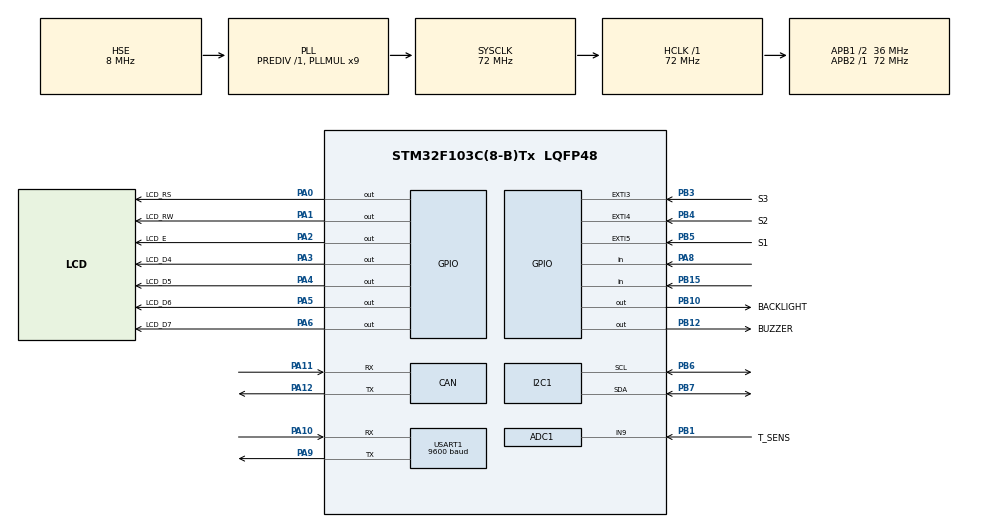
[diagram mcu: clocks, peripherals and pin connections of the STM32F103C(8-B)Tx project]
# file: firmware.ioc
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Mcu.Family=STM32F1
ADC1.ContinuousConvMode=ENABLE
PB4.GPIO_ModeDefaultEXTI=GPIO_MODE_IT_RISING_FALLING
USART1.BaudRate=9600
NVIC.EXTI3_IRQn=true\:0\:0\:false\:false\:true\:true\:true
PA11.Mode=Master
PA6.GPIO_Label=LCD_D7
PB3.GPIO_ModeDefaultEXTI=GPIO_MODE_IT_RISING_FALLING
PB15.Signal=GPIO_Input
RCC.SYSCLKSource=RCC_SYSCLKSOURCE_PLLCLK
ProjectManager.StackSize=0x400
PD1-OSC_OUT.Signal=RCC_OSC_OUT
PA12.Signal=CAN_TX
RCC.HCLKFreq_Value=72000000
RCC.APB2TimFreq_Value=72000000
PB6.Signal=I2C1_SCL
PB6.Mode=I2C
RCC.AHBFreq_Value=72000000
ADC1.Channel-0\#ChannelRegularConversion=ADC_CHANNEL_9
RCC.PLLMUL=RCC_PLL_MUL9
PB12.GPIO_Label=BUZZER
PB3.GPIO_PuPd=GPIO_PULLUP
PB1.GPIO_Label=T_SENS
PB7.Signal=I2C1_SDA
PA8.Signal=GPIO_Input
CAN.CalculateTimeQuantum=444.44444444444446
ADC1.SamplingTime-0\#ChannelRegularConversion=ADC_SAMPLETIME_1CYCLE_5
Mcu.Package=LQFP48
PB1.Signal=ADCx_IN9
PA6.Signal=GPIO_Output
PA2.GPIO_Label=LCD_E
PA10.Signal=USART1_RX
SH.ADCx_IN9.0=ADC1_IN9,IN9
PB5.GPIO_Label=S1
RCC.APB1TimFreq_Value=72000000
PA4.GPIO_Label=LCD_D5
PB4.Signal=GPXTI4
PA3.Signal=GPIO_Output
PB3.GPIO_Label=S3
PB5.GPIO_ModeDefaultEXTI=GPIO_MODE_IT_RISING_FALLING
RCC.PLLSourceVirtual=RCC_PLLSOURCE_HSE
NVIC.EXTI4_IRQn=true\:0\:0\:false\:false\:true\:true\:true
ADC1.Rank-0\#ChannelRegularConversion=1
PD1-OSC_OUT.Mode=HSE-External-Oscillator
PA10.Mode=Asynchronous
PD0-OSC_IN.Signal=RCC_OSC_IN
RCC.APB1CLKDivider=RCC_HCLK_DIV2
VP_SYS_VS_ND.Mode=No_Debug
CAN.CalculateTimeBit=2222
PA0-WKUP.GPIO_Label=LCD_RS
PA0-WKUP.Signal=GPIO_Output
RCC.ADCPresc=RCC_ADCPCLK2_DIV6
PA9.Mode=Asynchronous
CAN.BS2=CAN_BS2_2TQ
CAN.BS1=CAN_BS1_2TQ
ProjectManager.TargetToolchain=Makefile
PB10.GPIO_Label=BACKLIGHT
PA9.Signal=USART1_TX
PB4.GPIO_PuPd=GPIO_PULLUP
RCC.USBFreq_Value=72000000
PA1.Signal=GPIO_Output
PD0-OSC_IN.Mode=HSE-External-Oscillator
PB10.Signal=GPIO_Output
PA5.Signal=GPIO_Output
board=custom
RCC.APB2Freq_Value=72000000
PB4.GPIO_Label=S2
PA1.GPIO_Label=LCD_RW
Mcu.Name=STM32F103C(8-B)Tx
PA2.Signal=GPIO_Output
PB3.Signal=GPXTI3
PA4.Signal=GPIO_Output
RCC.SYSCLKFreq_VALUE=72000000
PB5.Signal=GPXTI5
ADC1.master=1
PA12.Mode=Master
PA5.GPIO_Label=LCD_D6
PB5.GPIO_PuPd=GPIO_PULLUP
USART1.VirtualMode=VM_ASYNC
PB7.Mode=I2C
PA11.Signal=CAN_RX
NVIC.EXTI9_5_IRQn=true\:0\:0\:false\:false\:true\:true\:true
ProjectManager.HeapSize=0x200
NVIC.PriorityGroup=NVIC_PRIORITYGROUP_4
ADC1.NbrOfConversionFlag=1
RCC.APB1Freq_Value=36000000
PB12.Signal=GPIO_Output
PA3.GPIO_Label=LCD_D4

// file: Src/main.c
/* USER CODE BEGIN Header */
/**
  ******************************************************************************
  * @file           : main.c
  * @brief          : Main program body
  ******************************************************************************
  * @attention
  *
  * <h2><center>&copy; Copyright (c) 2020 STMicroelectronics.
  * All rights reserved.</center></h2>
  *
  * This software component is licensed by ST under BSD 3-Clause license,
  * the "License"; You may not use this file except in compliance with the
  * License. You may obtain a copy of the License at:
  *                        opensource.org/licenses/BSD-3-Clause
  *
  ******************************************************************************
  */
/* USER CODE END Header */

#include "main.h"

/* USER CODE BEGIN Includes */

#include "logic.h"
#include "system.h"

/* USER CODE END Includes */

ADC_HandleTypeDef hadc1;

CAN_HandleTypeDef hcan;

I2C_HandleTypeDef hi2c1;

UART_HandleTypeDef huart1;

void SystemClock_Config(void);
static void MX_GPIO_Init(void);
static void MX_ADC1_Init(void);
static void MX_CAN_Init(void);
static void MX_I2C1_Init(void);
static void MX_USART1_UART_Init(void);

int main(void)
{

  /* MCU Configuration--------------------------------------------------------*/

  /* Reset of all peripherals, Initializes the Flash interface and the Systick. */
  HAL_Init();

  /* Configure the system clock */
  SystemClock_Config();

  /* Initialize all configured peripherals */
  MX_GPIO_Init();
  MX_ADC1_Init();
  MX_CAN_Init();
  MX_I2C1_Init();
  MX_USART1_UART_Init();
  /* USER CODE BEGIN 2 */

  system_init();
  logic_init();

  /* USER CODE END 2 */

  /* Infinite loop */
  /* USER CODE BEGIN WHILE */
  while (1)
  {
    logic_update();
    /* USER CODE END WHILE */

  }
}

void SystemClock_Config(void)
{
  RCC_OscInitTypeDef RCC_OscInitStruct = {0};
  RCC_ClkInitTypeDef RCC_ClkInitStruct = {0};
  RCC_PeriphCLKInitTypeDef PeriphClkInit = {0};

  /** Initializes the CPU, AHB and APB busses clocks
  */
  RCC_OscInitStruct.OscillatorType = RCC_OSCILLATORTYPE_HSE;
  RCC_OscInitStruct.HSEState = RCC_HSE_ON;
  RCC_OscInitStruct.HSEPredivValue = RCC_HSE_PREDIV_DIV1;
  RCC_OscInitStruct.HSIState = RCC_HSI_ON;
  RCC_OscInitStruct.PLL.PLLState = RCC_PLL_ON;
  RCC_OscInitStruct.PLL.PLLSource = RCC_PLLSOURCE_HSE;
  RCC_OscInitStruct.PLL.PLLMUL = RCC_PLL_MUL9;
  if (HAL_RCC_OscConfig(&RCC_OscInitStruct) != HAL_OK)
  {
    Error_Handler();
  }
  /** Initializes the CPU, AHB and APB busses clocks
  */
  RCC_ClkInitStruct.ClockType = RCC_CLOCKTYPE_HCLK|RCC_CLOCKTYPE_SYSCLK
                              |RCC_CLOCKTYPE_PCLK1|RCC_CLOCKTYPE_PCLK2;
  RCC_ClkInitStruct.SYSCLKSource = RCC_SYSCLKSOURCE_PLLCLK;
  RCC_ClkInitStruct.AHBCLKDivider = RCC_SYSCLK_DIV1;
  RCC_ClkInitStruct.APB1CLKDivider = RCC_HCLK_DIV2;
  RCC_ClkInitStruct.APB2CLKDivider = RCC_HCLK_DIV1;

  if (HAL_RCC_ClockConfig(&RCC_ClkInitStruct, FLASH_LATENCY_2) != HAL_OK)
  {
    Error_Handler();
  }
  PeriphClkInit.PeriphClockSelection = RCC_PERIPHCLK_ADC;
  PeriphClkInit.AdcClockSelection = RCC_ADCPCLK2_DIV6;
  if (HAL_RCCEx_PeriphCLKConfig(&PeriphClkInit) != HAL_OK)
  {
    Error_Handler();
  }
}

static void MX_ADC1_Init(void)
{

  ADC_ChannelConfTypeDef sConfig = {0};

  /** Common config
  */
  hadc1.Instance = ADC1;
  hadc1.Init.ScanConvMode = ADC_SCAN_DISABLE;
  hadc1.Init.ContinuousConvMode = ENABLE;
  hadc1.Init.DiscontinuousConvMode = DISABLE;
  hadc1.Init.ExternalTrigConv = ADC_SOFTWARE_START;
  hadc1.Init.DataAlign = ADC_DATAALIGN_RIGHT;
  hadc1.Init.NbrOfConversion = 1;
  if (HAL_ADC_Init(&hadc1) != HAL_OK)
  {
    Error_Handler();
  }
  /** Configure Regular Channel
  */
  sConfig.Channel = ADC_CHANNEL_9;
  sConfig.Rank = ADC_REGULAR_RANK_1;
  sConfig.SamplingTime = ADC_SAMPLETIME_1CYCLE_5;
  if (HAL_ADC_ConfigChannel(&hadc1, &sConfig) != HAL_OK)
  {
    Error_Handler();
  }

}

static void MX_CAN_Init(void)
{

  hcan.Instance = CAN1;
  hcan.Init.Prescaler = 16;
  hcan.Init.Mode = CAN_MODE_NORMAL;
  hcan.Init.SyncJumpWidth = CAN_SJW_1TQ;
  hcan.Init.TimeSeg1 = CAN_BS1_2TQ;
  hcan.Init.TimeSeg2 = CAN_BS2_2TQ;
  hcan.Init.TimeTriggeredMode = DISABLE;
  hcan.Init.AutoBusOff = DISABLE;
  hcan.Init.AutoWakeUp = DISABLE;
  hcan.Init.AutoRetransmission = DISABLE;
  hcan.Init.ReceiveFifoLocked = DISABLE;
  hcan.Init.TransmitFifoPriority = DISABLE;
  if (HAL_CAN_Init(&hcan) != HAL_OK)
  {
    Error_Handler();
  }

}

static void MX_I2C1_Init(void)
{

  hi2c1.Instance = I2C1;
  hi2c1.Init.ClockSpeed = 100000;
  hi2c1.Init.DutyCycle = I2C_DUTYCYCLE_2;
  hi2c1.Init.OwnAddress1 = 0;
  hi2c1.Init.AddressingMode = I2C_ADDRESSINGMODE_7BIT;
  hi2c1.Init.DualAddressMode = I2C_DUALADDRESS_DISABLE;
  hi2c1.Init.OwnAddress2 = 0;
  hi2c1.Init.GeneralCallMode = I2C_GENERALCALL_DISABLE;
  hi2c1.Init.NoStretchMode = I2C_NOSTRETCH_DISABLE;
  if (HAL_I2C_Init(&hi2c1) != HAL_OK)
  {
    Error_Handler();
  }

}

static void MX_USART1_UART_Init(void)
{

  huart1.Instance = USART1;
  huart1.Init.BaudRate = 9600;
  huart1.Init.WordLength = UART_WORDLENGTH_8B;
  huart1.Init.StopBits = UART_STOPBITS_1;
  huart1.Init.Parity = UART_PARITY_NONE;
  huart1.Init.Mode = UART_MODE_TX_RX;
  huart1.Init.HwFlowCtl = UART_HWCONTROL_NONE;
  huart1.Init.OverSampling = UART_OVERSAMPLING_16;
  if (HAL_UART_Init(&huart1) != HAL_OK)
  {
    Error_Handler();
  }

}

static void MX_GPIO_Init(void)
{
  GPIO_InitTypeDef GPIO_InitStruct = {0};

  /* GPIO Ports Clock Enable */
  __HAL_RCC_GPIOD_CLK_ENABLE();
  __HAL_RCC_GPIOA_CLK_ENABLE();
  __HAL_RCC_GPIOB_CLK_ENABLE();

  /*Configure GPIO pin Output Level */
  HAL_GPIO_WritePin(GPIOA, LCD_RS_Pin|LCD_RW_Pin|LCD_E_Pin|LCD_D4_Pin
                          |LCD_D5_Pin|LCD_D6_Pin|LCD_D7_Pin, GPIO_PIN_RESET);

  /*Configure GPIO pin Output Level */
  HAL_GPIO_WritePin(GPIOB, BACKLIGHT_Pin|BUZZER_Pin, GPIO_PIN_RESET);

  /*Configure GPIO pins : LCD_RS_Pin LCD_RW_Pin LCD_E_Pin LCD_D4_Pin
                           LCD_D5_Pin LCD_D6_Pin LCD_D7_Pin */
  GPIO_InitStruct.Pin = LCD_RS_Pin|LCD_RW_Pin|LCD_E_Pin|LCD_D4_Pin
                          |LCD_D5_Pin|LCD_D6_Pin|LCD_D7_Pin;
  GPIO_InitStruct.Mode = GPIO_MODE_OUTPUT_PP;
  GPIO_InitStruct.Pull = GPIO_NOPULL;
  GPIO_InitStruct.Speed = GPIO_SPEED_FREQ_LOW;
  HAL_GPIO_Init(GPIOA, &GPIO_InitStruct);

  /*Configure GPIO pins : BACKLIGHT_Pin BUZZER_Pin */
  GPIO_InitStruct.Pin = BACKLIGHT_Pin|BUZZER_Pin;
  GPIO_InitStruct.Mode = GPIO_MODE_OUTPUT_PP;
  GPIO_InitStruct.Pull = GPIO_NOPULL;
  GPIO_InitStruct.Speed = GPIO_SPEED_FREQ_LOW;
  HAL_GPIO_Init(GPIOB, &GPIO_InitStruct);

  /*Configure GPIO pin : PB15 */
  GPIO_InitStruct.Pin = GPIO_PIN_15;
  GPIO_InitStruct.Mode = GPIO_MODE_INPUT;
  GPIO_InitStruct.Pull = GPIO_NOPULL;
  HAL_GPIO_Init(GPIOB, &GPIO_InitStruct);

  /*Configure GPIO pin : PA8 */
  GPIO_InitStruct.Pin = GPIO_PIN_8;
  GPIO_InitStruct.Mode = GPIO_MODE_INPUT;
  GPIO_InitStruct.Pull = GPIO_NOPULL;
  HAL_GPIO_Init(GPIOA, &GPIO_InitStruct);

  /*Configure GPIO pins : S3_Pin S2_Pin S1_Pin */
  GPIO_InitStruct.Pin = S3_Pin|S2_Pin|S1_Pin;
  GPIO_InitStruct.Mode = GPIO_MODE_IT_RISING_FALLING;
  GPIO_InitStruct.Pull = GPIO_PULLUP;
  HAL_GPIO_Init(GPIOB, &GPIO_InitStruct);

  /* EXTI interrupt init*/
  HAL_NVIC_SetPriority(EXTI3_IRQn, 0, 0);
  HAL_NVIC_EnableIRQ(EXTI3_IRQn);

  HAL_NVIC_SetPriority(EXTI4_IRQn, 0, 0);
  HAL_NVIC_EnableIRQ(EXTI4_IRQn);

  HAL_NVIC_SetPriority(EXTI9_5_IRQn, 0, 0);
  HAL_NVIC_EnableIRQ(EXTI9_5_IRQn);

}

void Error_Handler(void)
{
}

/************************ (C) COPYRIGHT STMicroelectronics *****END OF FILE****/
